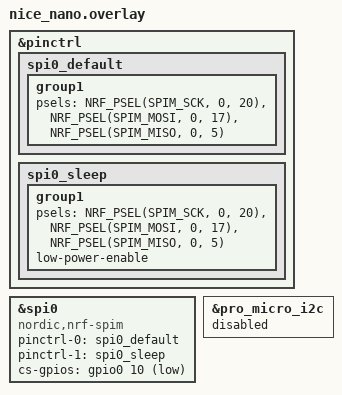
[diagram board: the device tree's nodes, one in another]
/*
 * Copyright (c) 2024 The ZMK Contributors
 * SPDX-License-Identifier: MIT
 */

&pinctrl {
  spi0_default: spi0_default {
    group1 {
      psels =
        <NRF_PSEL(SPIM_SCK, 0, 20)>,
        <NRF_PSEL(SPIM_MOSI, 0, 17)>,
        <NRF_PSEL(SPIM_MISO, 0, 5)>;
    };
  };

  spi0_sleep: spi0_sleep {
    group1 {
      psels =
        <NRF_PSEL(SPIM_SCK, 0, 20)>,
        <NRF_PSEL(SPIM_MOSI, 0, 17)>,
        <NRF_PSEL(SPIM_MISO, 0, 5)>;
      low-power-enable;
    };
  };
};

spi_gooddisplay: &spi0 {
  compatible = "nordic,nrf-spim";
  status = "okay";
  pinctrl-0 = <&spi0_default>;
  pinctrl-1 = <&spi0_sleep>;
  pinctrl-names = "default", "sleep";
  cs-gpios = <&gpio0 10 GPIO_ACTIVE_LOW>;
};


&pro_micro_i2c {
  status = "disabled";
};
